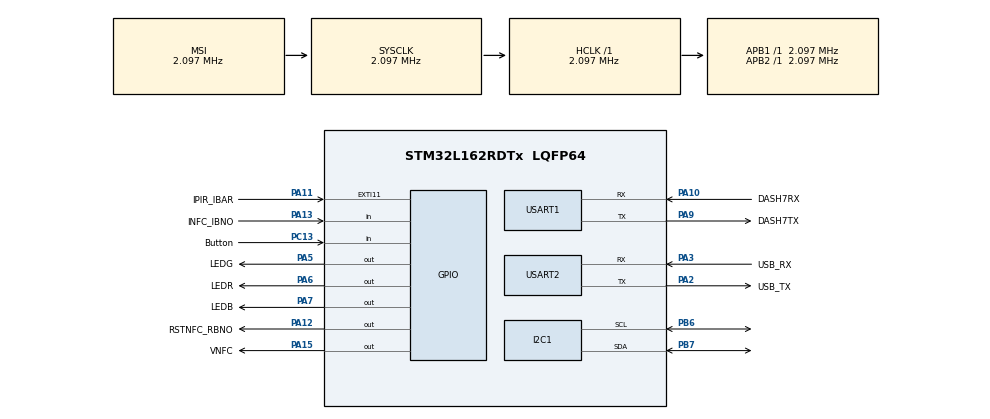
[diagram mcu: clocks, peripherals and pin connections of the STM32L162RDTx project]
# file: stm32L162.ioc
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Mcu.Family=STM32L1
Mcu.Name=STM32L162RDTx
Mcu.Package=LQFP64
NVIC.PriorityGroup=NVIC_PRIORITYGROUP_4
NVIC.TIM2_IRQn=true\:0\:0\:false\:false\:true
PA10.GPIO_Label=DASH7RX
PA10.Mode=Asynchronous
PA10.Signal=USART1_RX
PA11.GPIO_Label=IPIR_IBAR
PA11.Signal=GPXTI11
PA12.GPIO_Label=RSTNFC_RBNO
PA12.Signal=GPIO_Output
PA13.GPIO_Label=INFC_IBNO
PA13.Signal=GPIO_Input
PA15.GPIO_Label=VNFC
PA15.Signal=GPIO_Output
PA2.GPIO_Label=USB_TX
PA2.Mode=Asynchronous
PA2.Signal=USART2_TX
PA3.GPIO_Label=USB_RX
PA3.Mode=Asynchronous
PA3.Signal=USART2_RX
PA5.GPIO_Label=LEDG
PA5.PinState=GPIO_PIN_RESET
PA5.Signal=GPIO_Output
PA6.GPIO_Label=LEDR
PA6.Signal=GPIO_Output
PA7.GPIO_Label=LEDB
PA7.Signal=GPIO_Output
PA9.GPIO_Label=DASH7TX
PA9.Mode=Asynchronous
PA9.Signal=USART1_TX
PB6.Mode=I2C
PB6.Signal=I2C1_SCL
PB7.Mode=I2C
PB7.Signal=I2C1_SDA
PC13-WKUP2.GPIO_Label=Button
PC13-WKUP2.Signal=GPIO_Input
ProjectManager.HeapSize=0x200
ProjectManager.StackSize=0x400
ProjectManager.TargetToolchain=SW4STM32
RCC.AHBFreq_Value=2097000
RCC.APB1Freq_Value=2097000
RCC.APB2Freq_Value=2097000
RCC.HSE_VALUE=24000000
RCC.HSI_VALUE=16000000
RCC.LSE_VALUE=32768
RCC.MSI_VALUE=2097000
RCC.SYSCLKFreq_VALUE=2097000
RCC.VCOOutputFreq_Value=48000000
TIM2.Period=499
TIM2.Prescaler=2000
USART1.VirtualMode=VM_ASYNC
USART2.VirtualMode=VM_ASYNC
VP_TIM2_VS_ClockSourceINT.Mode=Internal
board=stm32L162

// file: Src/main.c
/**
  ******************************************************************************
  * File Name          : main.c
  * Description        : Main program body
  ******************************************************************************
  *
  * COPYRIGHT(c) 2017 STMicroelectronics
  *
  * Redistribution and use in source and binary forms, with or without modification,
  * are permitted provided that the following conditions are met:
  *   1. Redistributions of source code must retain the above copyright notice,
  *      this list of conditions and the following disclaimer.
  *   2. Redistributions in binary form must reproduce the above copyright notice,
  *      this list of conditions and the following disclaimer in the documentation
  *      and/or other materials provided with the distribution.
  *   3. Neither the name of STMicroelectronics nor the names of its contributors
  *      may be used to endorse or promote products derived from this software
  *      without specific prior written permission.
  *
  * THIS SOFTWARE IS PROVIDED BY THE COPYRIGHT HOLDERS AND CONTRIBUTORS "AS IS"
  * AND ANY EXPRESS OR IMPLIED WARRANTIES, INCLUDING, BUT NOT LIMITED TO, THE
  * IMPLIED WARRANTIES OF MERCHANTABILITY AND FITNESS FOR A PARTICULAR PURPOSE ARE
  * DISCLAIMED. IN NO EVENT SHALL THE COPYRIGHT HOLDER OR CONTRIBUTORS BE LIABLE
  * FOR ANY DIRECT, INDIRECT, INCIDENTAL, SPECIAL, EXEMPLARY, OR CONSEQUENTIAL
  * DAMAGES (INCLUDING, BUT NOT LIMITED TO, PROCUREMENT OF SUBSTITUTE GOODS OR
  * SERVICES; LOSS OF USE, DATA, OR PROFITS; OR BUSINESS INTERRUPTION) HOWEVER
  * CAUSED AND ON ANY THEORY OF LIABILITY, WHETHER IN CONTRACT, STRICT LIABILITY,
  * OR TORT (INCLUDING NEGLIGENCE OR OTHERWISE) ARISING IN ANY WAY OUT OF THE USE
  * OF THIS SOFTWARE, EVEN IF ADVISED OF THE POSSIBILITY OF SUCH DAMAGE.
  *
  ******************************************************************************
  */
#include "main.h"
#include "stm32l1xx_hal.h"

I2C_HandleTypeDef hi2c1;

TIM_HandleTypeDef htim2;

UART_HandleTypeDef huart1;
UART_HandleTypeDef huart2;

/* USER CODE BEGIN PV */
/* Private variables ---------------------------------------------------------*/

/* USER CODE END PV */

void SystemClock_Config(void);
void Error_Handler(void);
static void MX_GPIO_Init(void);
static void MX_I2C1_Init(void);
static void MX_USART1_UART_Init(void);
static void MX_USART2_UART_Init(void);
static void MX_TIM2_Init(void);

/* USER CODE BEGIN PFP */
/* Private function prototypes -----------------------------------------------*/

/* USER CODE END PFP */

int main(void)
{

  /* MCU Configuration----------------------------------------------------------*/

  /* Reset of all peripherals, Initializes the Flash interface and the Systick. */
  HAL_Init();

  /* Configure the system clock */
  SystemClock_Config();

  /* Initialize all configured peripherals */
  MX_GPIO_Init();
  MX_I2C1_Init();
  MX_USART1_UART_Init();
  MX_USART2_UART_Init();
  MX_TIM2_Init();

  /* USER CODE BEGIN 2 */

	//Enable and start timer interrupt
   MX_TIM2_Init();
   __HAL_RCC_TIM2_CLK_ENABLE(); //Enable the TIM2 peripheral
   HAL_NVIC_SetPriority(TIM2_IRQn, 0, 0); //Enable the peripheral IRQ
   HAL_NVIC_EnableIRQ(TIM2_IRQn);
   HAL_TIM_Base_Init(&htim2); //Configure the timer
   HAL_TIM_Base_Start_IT(&htim2); //Start the timer
  /* USER CODE END 2 */

  /* Infinite loop */
  while (1)
  {

  }

}

/** System Clock Configuration
*/
void SystemClock_Config(void)
{

  RCC_OscInitTypeDef RCC_OscInitStruct;
  RCC_ClkInitTypeDef RCC_ClkInitStruct;

    /**Configure the main internal regulator output voltage
    */
  __HAL_PWR_VOLTAGESCALING_CONFIG(PWR_REGULATOR_VOLTAGE_SCALE1);

    /**Initializes the CPU, AHB and APB busses clocks
    */
  RCC_OscInitStruct.OscillatorType = RCC_OSCILLATORTYPE_MSI;
  RCC_OscInitStruct.MSIState = RCC_MSI_ON;
  RCC_OscInitStruct.MSICalibrationValue = 0;
  RCC_OscInitStruct.MSIClockRange = RCC_MSIRANGE_5;
  RCC_OscInitStruct.PLL.PLLState = RCC_PLL_NONE;
  if (HAL_RCC_OscConfig(&RCC_OscInitStruct) != HAL_OK)
  {
    Error_Handler();
  }

    /**Initializes the CPU, AHB and APB busses clocks
    */
  RCC_ClkInitStruct.ClockType = RCC_CLOCKTYPE_HCLK|RCC_CLOCKTYPE_SYSCLK
                              |RCC_CLOCKTYPE_PCLK1|RCC_CLOCKTYPE_PCLK2;
  RCC_ClkInitStruct.SYSCLKSource = RCC_SYSCLKSOURCE_MSI;
  RCC_ClkInitStruct.AHBCLKDivider = RCC_SYSCLK_DIV1;
  RCC_ClkInitStruct.APB1CLKDivider = RCC_HCLK_DIV1;
  RCC_ClkInitStruct.APB2CLKDivider = RCC_HCLK_DIV1;

  if (HAL_RCC_ClockConfig(&RCC_ClkInitStruct, FLASH_LATENCY_0) != HAL_OK)
  {
    Error_Handler();
  }

    /**Configure the Systick interrupt time
    */
  HAL_SYSTICK_Config(HAL_RCC_GetHCLKFreq()/1000);

    /**Configure the Systick
    */
  HAL_SYSTICK_CLKSourceConfig(SYSTICK_CLKSOURCE_HCLK);

  /* SysTick_IRQn interrupt configuration */
  HAL_NVIC_SetPriority(SysTick_IRQn, 0, 0);
}

/* I2C1 init function */
static void MX_I2C1_Init(void)
{

  hi2c1.Instance = I2C1;
  hi2c1.Init.ClockSpeed = 100000;
  hi2c1.Init.DutyCycle = I2C_DUTYCYCLE_2;
  hi2c1.Init.OwnAddress1 = 0;
  hi2c1.Init.AddressingMode = I2C_ADDRESSINGMODE_7BIT;
  hi2c1.Init.DualAddressMode = I2C_DUALADDRESS_DISABLE;
  hi2c1.Init.OwnAddress2 = 0;
  hi2c1.Init.GeneralCallMode = I2C_GENERALCALL_DISABLE;
  hi2c1.Init.NoStretchMode = I2C_NOSTRETCH_DISABLE;
  if (HAL_I2C_Init(&hi2c1) != HAL_OK)
  {
    Error_Handler();
  }

}

/* TIM2 init function */
static void MX_TIM2_Init(void)
{

  TIM_ClockConfigTypeDef sClockSourceConfig;
  TIM_MasterConfigTypeDef sMasterConfig;

  htim2.Instance = TIM2;
  htim2.Init.Prescaler = 2000;
  htim2.Init.CounterMode = TIM_COUNTERMODE_UP;
  htim2.Init.Period = 499;
  htim2.Init.ClockDivision = TIM_CLOCKDIVISION_DIV1;
  if (HAL_TIM_Base_Init(&htim2) != HAL_OK)
  {
    Error_Handler();
  }

  sClockSourceConfig.ClockSource = TIM_CLOCKSOURCE_INTERNAL;
  if (HAL_TIM_ConfigClockSource(&htim2, &sClockSourceConfig) != HAL_OK)
  {
    Error_Handler();
  }

  sMasterConfig.MasterOutputTrigger = TIM_TRGO_RESET;
  sMasterConfig.MasterSlaveMode = TIM_MASTERSLAVEMODE_DISABLE;
  if (HAL_TIMEx_MasterConfigSynchronization(&htim2, &sMasterConfig) != HAL_OK)
  {
    Error_Handler();
  }

}

/* USART1 init function */
static void MX_USART1_UART_Init(void)
{

  huart1.Instance = USART1;
  huart1.Init.BaudRate = 115200;
  huart1.Init.WordLength = UART_WORDLENGTH_8B;
  huart1.Init.StopBits = UART_STOPBITS_1;
  huart1.Init.Parity = UART_PARITY_NONE;
  huart1.Init.Mode = UART_MODE_TX_RX;
  huart1.Init.HwFlowCtl = UART_HWCONTROL_NONE;
  huart1.Init.OverSampling = UART_OVERSAMPLING_16;
  if (HAL_UART_Init(&huart1) != HAL_OK)
  {
    Error_Handler();
  }

}

/* USART2 init function */
static void MX_USART2_UART_Init(void)
{

  huart2.Instance = USART2;
  huart2.Init.BaudRate = 115200;
  huart2.Init.WordLength = UART_WORDLENGTH_8B;
  huart2.Init.StopBits = UART_STOPBITS_1;
  huart2.Init.Parity = UART_PARITY_NONE;
  huart2.Init.Mode = UART_MODE_TX_RX;
  huart2.Init.HwFlowCtl = UART_HWCONTROL_NONE;
  huart2.Init.OverSampling = UART_OVERSAMPLING_16;
  if (HAL_UART_Init(&huart2) != HAL_OK)
  {
    Error_Handler();
  }

}

/** Configure pins as
        * Analog
        * Input
        * Output
        * EVENT_OUT
        * EXTI
*/
static void MX_GPIO_Init(void)
{

  GPIO_InitTypeDef GPIO_InitStruct;

  /* GPIO Ports Clock Enable */
  __HAL_RCC_GPIOC_CLK_ENABLE();
  __HAL_RCC_GPIOA_CLK_ENABLE();
  __HAL_RCC_GPIOB_CLK_ENABLE();

  /*Configure GPIO pin Output Level */
  HAL_GPIO_WritePin(GPIOA, LEDG_Pin|LEDR_Pin|LEDB_Pin|RSTNFC_RBNO_Pin
                          |VNFC_Pin, GPIO_PIN_RESET);

  /*Configure GPIO pin : Button_Pin */
  GPIO_InitStruct.Pin = Button_Pin;
  GPIO_InitStruct.Mode = GPIO_MODE_INPUT;
  GPIO_InitStruct.Pull = GPIO_NOPULL;
  HAL_GPIO_Init(Button_GPIO_Port, &GPIO_InitStruct);

  /*Configure GPIO pins : LEDG_Pin LEDR_Pin LEDB_Pin RSTNFC_RBNO_Pin
                           VNFC_Pin */
  GPIO_InitStruct.Pin = LEDG_Pin|LEDR_Pin|LEDB_Pin|RSTNFC_RBNO_Pin
                          |VNFC_Pin;
  GPIO_InitStruct.Mode = GPIO_MODE_OUTPUT_PP;
  GPIO_InitStruct.Pull = GPIO_NOPULL;
  GPIO_InitStruct.Speed = GPIO_SPEED_FREQ_LOW;
  HAL_GPIO_Init(GPIOA, &GPIO_InitStruct);

  /*Configure GPIO pin : IPIR_IBAR_Pin */
  GPIO_InitStruct.Pin = IPIR_IBAR_Pin;
  GPIO_InitStruct.Mode = GPIO_MODE_IT_RISING;
  GPIO_InitStruct.Pull = GPIO_NOPULL;
  HAL_GPIO_Init(IPIR_IBAR_GPIO_Port, &GPIO_InitStruct);

  /*Configure GPIO pin : INFC_IBNO_Pin */
  GPIO_InitStruct.Pin = INFC_IBNO_Pin;
  GPIO_InitStruct.Mode = GPIO_MODE_INPUT;
  GPIO_InitStruct.Pull = GPIO_NOPULL;
  HAL_GPIO_Init(INFC_IBNO_GPIO_Port, &GPIO_InitStruct);

}

/* USER CODE BEGIN 4 */
/*void TIM2_IRQHandler(void)
{
      //if more than 1 timer is used with interrupts enabled, we have to manually check which interrupt flag has been set
     HAL_TIM_IRQHandler(&htim2);
}*/

void HAL_TIM_PeriodElapsedCallback(TIM_HandleTypeDef *htim) {
    if(htim->Instance==TIM2)
    {
      //INTERRUPT CALLBACK
    }

}

/* USER CODE END 4 */

void Error_Handler(void)
{
  while(1)
  {
  }
}

/************************ (C) COPYRIGHT STMicroelectronics *****END OF FILE****/
